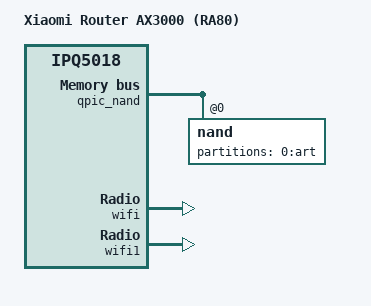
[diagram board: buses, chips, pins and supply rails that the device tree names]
// SPDX-License-Identifier: GPL-2.0-or-later OR MIT

/dts-v1/;

#include "ipq5018-cr880x.dtsi"

/ {
	model = "Xiaomi Router AX3000 (RA80)";
	compatible = "xiaomi,ax3000", "xiaomi,cr8806", "qcom,ipq5018";
};

&qpic_nand {
	nand@0 {
		partitions {
			compatible = "qcom,smem-part";

			partition-art {
				label = "0:art";
				read-only;

				nvmem-layout {
					compatible = "fixed-layout";
					#address-cells = <1>;
					#size-cells = <1>;

					macaddr_art_0: mac-address@0 {
						compatible = "mac-base";
						reg = <0x0 0x6>;
						#nvmem-cell-cells = <1>;
					};

					macaddr_art_6: mac-address@6 {
						compatible = "mac-base";
						reg = <0x6 0x6>;
						#nvmem-cell-cells = <1>;
					};
				};
			};
		};
	};
};

&wifi {
	qcom,ath11k-calibration-variant = "Xiaomi-AX3000";
};

&wifi1 {
	qcom,ath11k-calibration-variant = "Xiaomi-AX3000";
};
